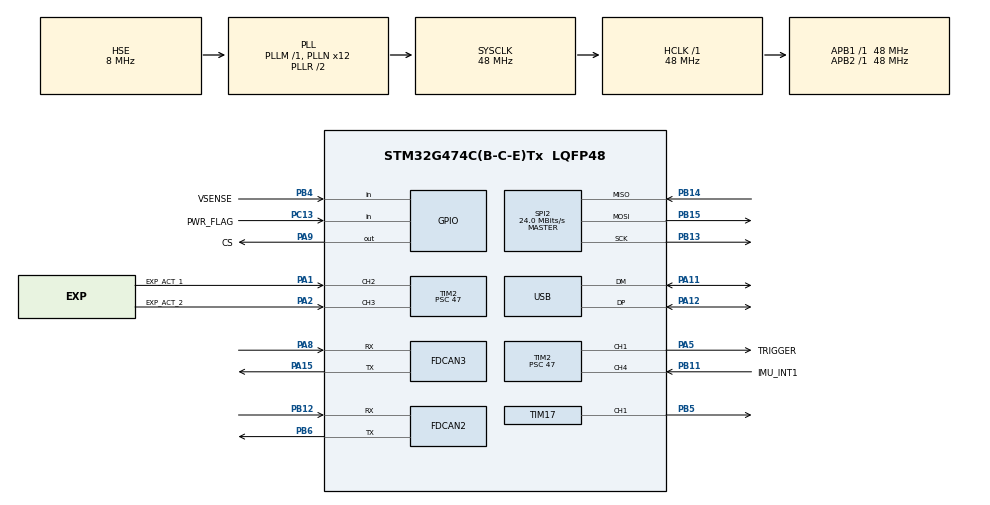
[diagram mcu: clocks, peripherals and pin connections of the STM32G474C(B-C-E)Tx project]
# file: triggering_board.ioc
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FDCAN2.AutoRetransmission=DISABLE
FDCAN2.CalculateBaudRateNominal=500000
FDCAN2.CalculateTimeBitNominal=2000
FDCAN2.CalculateTimeQuantumNominal=20.833333333333332
FDCAN2.DataPrescaler=24
FDCAN2.DataTimeSeg1=2
FDCAN2.FrameFormat=FDCAN_FRAME_CLASSIC
FDCAN2.Mode=FDCAN_MODE_NORMAL
FDCAN2.NominalPrescaler=1
FDCAN2.NominalSyncJumpWidth=12
FDCAN2.NominalTimeSeg1=83
FDCAN2.NominalTimeSeg2=12
FDCAN2.StdFiltersNbr=1
FDCAN3.AutoRetransmission=DISABLE
FDCAN3.CalculateBaudRateNominal=500000
FDCAN3.CalculateTimeBitNominal=2000
FDCAN3.CalculateTimeQuantumNominal=20.833333333333332
FDCAN3.DataPrescaler=24
FDCAN3.DataTimeSeg1=2
FDCAN3.FrameFormat=FDCAN_FRAME_FD_NO_BRS
FDCAN3.Mode=FDCAN_MODE_NORMAL
FDCAN3.NominalPrescaler=1
FDCAN3.NominalSyncJumpWidth=12
FDCAN3.NominalTimeSeg1=83
FDCAN3.NominalTimeSeg2=12
FDCAN3.StdFiltersNbr=1
Mcu.Family=STM32G4
Mcu.Name=STM32G474C(B-C-E)Tx
Mcu.Package=LQFP48
NVIC.FDCAN2_IT0_IRQn=true\:0\:0\:false\:false\:true\:true\:true\:true
NVIC.FDCAN3_IT0_IRQn=true\:0\:0\:false\:false\:true\:true\:true\:true
NVIC.PriorityGroup=NVIC_PRIORITYGROUP_4
NVIC.TIM2_IRQn=true\:0\:0\:false\:false\:true\:true\:true\:true
PA1.GPIO_Label=EXP_ACT_1
PA1.Signal=S_TIM2_CH2
PA11.Mode=Device
PA11.Signal=USB_DM
PA12.Mode=Device
PA12.Signal=USB_DP
PA13.Mode=Trace_Asynchronous_SW
PA13.Signal=SYS_JTMS-SWDIO
PA14.Mode=Trace_Asynchronous_SW
PA14.Signal=SYS_JTCK-SWCLK
PA15.Mode=FDCAN_Activate
PA15.Signal=FDCAN3_TX
PA2.GPIO_Label=EXP_ACT_2
PA2.Signal=S_TIM2_CH3
PA5.GPIO_Label=TRIGGER
PA5.Signal=S_TIM2_CH1
PA8.Mode=FDCAN_Activate
PA8.Signal=FDCAN3_RX
PA9.GPIO_Label=CS
PA9.Signal=GPIO_Output
PB11.GPIO_Label=IMU_INT1
PB11.Signal=S_TIM2_CH4
PB12.Mode=FDCAN_Activate
PB12.Signal=FDCAN2_RX
PB13.Mode=Full_Duplex_Master
PB13.Signal=SPI2_SCK
PB14.Mode=Full_Duplex_Master
PB14.Signal=SPI2_MISO
PB15.Mode=Full_Duplex_Master
PB15.Signal=SPI2_MOSI
PB3.Mode=Trace_Asynchronous_SW
PB3.Signal=SYS_JTDO-SWO
PB4.GPIO_Label=VSENSE
PB4.Signal=GPIO_Input
PB5.Signal=S_TIM17_CH1
PB6.Mode=FDCAN_Activate
PB6.Signal=FDCAN2_TX
PC13.GPIO_Label=PWR_FLAG
PC13.Signal=GPIO_Input
PC14-OSC32_IN.Mode=LSE-External-Oscillator
PC14-OSC32_IN.Signal=RCC_OSC32_IN
PC15-OSC32_OUT.Mode=LSE-External-Oscillator
PC15-OSC32_OUT.Signal=RCC_OSC32_OUT
PF0-OSC_IN.Mode=HSE-External-Oscillator
PF0-OSC_IN.Signal=RCC_OSC_IN
PF1-OSC_OUT.Mode=HSE-External-Oscillator
PF1-OSC_OUT.Signal=RCC_OSC_OUT
ProjectManager.HeapSize=0x200
ProjectManager.StackSize=0x400
ProjectManager.TargetToolchain=STM32CubeIDE
RCC.ADC12Freq_Value=48000000
RCC.ADC345Freq_Value=48000000
RCC.AHBFreq_Value=48000000
RCC.APB1Freq_Value=48000000
RCC.APB1TimFreq_Value=48000000
RCC.APB2Freq_Value=48000000
RCC.APB2TimFreq_Value=48000000
RCC.CortexFreq_Value=48000000
RCC.EXTERNAL_CLOCK_VALUE=12288000
RCC.HCLKFreq_Value=48000000
RCC.HSE_VALUE=8000000
RCC.HSI48_VALUE=48000000
RCC.HSI_VALUE=16000000
RCC.PLLN=12
RCC.PLLSourceVirtual=RCC_PLLSOURCE_HSE
RCC.SYSCLKFreq_VALUE=48000000
RCC.SYSCLKSource=RCC_SYSCLKSOURCE_PLLCLK
RCC.USBFreq_Value=48000000
RCC.VCOOutputFreq_Value=96000000
SH.S_TIM17_CH1.0=TIM17_CH1,PWM Generation1 CH1
SH.S_TIM2_CH1.0=TIM2_CH1,Output Compare1 CH1
SH.S_TIM2_CH2.0=TIM2_CH2,Input_Capture2_from_TI2
SH.S_TIM2_CH3.0=TIM2_CH3,Input_Capture3_from_TI3
SH.S_TIM2_CH4.0=TIM2_CH4,Input_Capture4_from_TI4
SPI2.BaudRatePrescaler=SPI_BAUDRATEPRESCALER_2
SPI2.CLKPhase=SPI_PHASE_1EDGE
SPI2.CLKPolarity=SPI_POLARITY_LOW
SPI2.CalculateBaudRate=24.0 MBits/s
SPI2.DataSize=SPI_DATASIZE_8BIT
SPI2.Direction=SPI_DIRECTION_2LINES
SPI2.Mode=SPI_MODE_MASTER
SPI2.VirtualType=VM_MASTER
TIM17.Channel=TIM_CHANNEL_1
TIM17.PeriodNoDither=999
TIM17.Prescaler=47
TIM17.PulseNoDither_1=100
TIM2.Channel-Input_Capture2_from_TI2=TIM_CHANNEL_2
TIM2.Channel-Input_Capture3_from_TI3=TIM_CHANNEL_3
TIM2.Channel-Input_Capture4_from_TI4=TIM_CHANNEL_4
TIM2.Channel-Output\ Compare1\ CH1=TIM_CHANNEL_1
TIM2.ICPolarity_CH2=TIM_INPUTCHANNELPOLARITY_BOTHEDGE
TIM2.ICPolarity_CH3=TIM_INPUTCHANNELPOLARITY_BOTHEDGE
TIM2.OCMode_1=TIM_OCMODE_TOGGLE
TIM2.Prescaler=47
TIM2.PulseNoDither_1=4294967295
VP_SYS_VS_DBSignals.Mode=DisableDeadBatterySignals
VP_TIM17_VS_ClockSourceINT.Mode=Enable_Timer
VP_TIM2_VS_ClockSourceINT.Mode=Internal
board=custom

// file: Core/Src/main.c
/* USER CODE BEGIN Header */
/**
  ******************************************************************************
  * @file           : main.c
  * @brief          : Main program body
  ******************************************************************************
  * @attention
  *
  * Copyright (c) 2026 STMicroelectronics.
  * All rights reserved.
  *
  * This software is licensed under terms that can be found in the LICENSE file
  * in the root directory of this software component.
  * If no LICENSE file comes with this software, it is provided AS-IS.
  *
  ******************************************************************************
  */
/* USER CODE END Header */
#include "main.h"

FDCAN_HandleTypeDef hfdcan2;
FDCAN_HandleTypeDef hfdcan3;

SPI_HandleTypeDef hspi2;

TIM_HandleTypeDef htim2;
TIM_HandleTypeDef htim17;

PCD_HandleTypeDef hpcd_USB_FS;

void SystemClock_Config(void);
static void MX_GPIO_Init(void);
static void MX_FDCAN2_Init(void);
static void MX_FDCAN3_Init(void);
static void MX_SPI2_Init(void);
static void MX_USB_PCD_Init(void);
static void MX_TIM2_Init(void);
static void MX_TIM17_Init(void);

int main(void)
{

  /* MCU Configuration--------------------------------------------------------*/

  /* Reset of all peripherals, Initializes the Flash interface and the Systick. */
  HAL_Init();

  /* Configure the system clock */
  SystemClock_Config();

  /* Initialize all configured peripherals */
  MX_GPIO_Init();
  MX_FDCAN2_Init();
  MX_FDCAN3_Init();
  MX_SPI2_Init();
  MX_USB_PCD_Init();
  MX_TIM2_Init();
  MX_TIM17_Init();
  /* USER CODE BEGIN 2 */

  // Configure CAN
  configure_fdcan();

  // Start timer channels
  HAL_TIM_OC_Start_IT(&htim2, TIM_CHANNEL_1); // Start TRIGGER channel
  HAL_TIM_OC_Start_IT(&htim2, TIM_CHANNEL_2); // Start EXP_ACT_1 channel
  HAL_TIM_IC_Start_IT(&htim2, TIM_CHANNEL_3); // Start EXP_ACT_2 channel
  HAL_TIM_IC_Start_IT(&htim2, TIM_CHANNEL_4); // Start IMU_INT1 channel
  HAL_TIM_PWM_Start(&htim17, TIM_CHANNEL_1);

  /* USER CODE END 2 */

  /* Infinite loop */
  /* USER CODE BEGIN WHILE */
  while (1)
  {

	  state_machine_handler();

    /* USER CODE END WHILE */

  }
}

void SystemClock_Config(void)
{
  RCC_OscInitTypeDef RCC_OscInitStruct = {0};
  RCC_ClkInitTypeDef RCC_ClkInitStruct = {0};

  /** Configure the main internal regulator output voltage
  */
  HAL_PWREx_ControlVoltageScaling(PWR_REGULATOR_VOLTAGE_SCALE1);

  /** Initializes the RCC Oscillators according to the specified parameters
  * in the RCC_OscInitTypeDef structure.
  */
  RCC_OscInitStruct.OscillatorType = RCC_OSCILLATORTYPE_HSE;
  RCC_OscInitStruct.HSEState = RCC_HSE_ON;
  RCC_OscInitStruct.PLL.PLLState = RCC_PLL_ON;
  RCC_OscInitStruct.PLL.PLLSource = RCC_PLLSOURCE_HSE;
  RCC_OscInitStruct.PLL.PLLM = RCC_PLLM_DIV1;
  RCC_OscInitStruct.PLL.PLLN = 12;
  RCC_OscInitStruct.PLL.PLLP = RCC_PLLP_DIV2;
  RCC_OscInitStruct.PLL.PLLQ = RCC_PLLQ_DIV2;
  RCC_OscInitStruct.PLL.PLLR = RCC_PLLR_DIV2;
  if (HAL_RCC_OscConfig(&RCC_OscInitStruct) != HAL_OK)
  {
    Error_Handler();
  }

  /** Initializes the CPU, AHB and APB buses clocks
  */
  RCC_ClkInitStruct.ClockType = RCC_CLOCKTYPE_HCLK|RCC_CLOCKTYPE_SYSCLK
                              |RCC_CLOCKTYPE_PCLK1|RCC_CLOCKTYPE_PCLK2;
  RCC_ClkInitStruct.SYSCLKSource = RCC_SYSCLKSOURCE_PLLCLK;
  RCC_ClkInitStruct.AHBCLKDivider = RCC_SYSCLK_DIV1;
  RCC_ClkInitStruct.APB1CLKDivider = RCC_HCLK_DIV1;
  RCC_ClkInitStruct.APB2CLKDivider = RCC_HCLK_DIV1;

  if (HAL_RCC_ClockConfig(&RCC_ClkInitStruct, FLASH_LATENCY_1) != HAL_OK)
  {
    Error_Handler();
  }
}

static void MX_FDCAN2_Init(void)
{

  hfdcan2.Instance = FDCAN2;
  hfdcan2.Init.ClockDivider = FDCAN_CLOCK_DIV1;
  hfdcan2.Init.FrameFormat = FDCAN_FRAME_CLASSIC;
  hfdcan2.Init.Mode = FDCAN_MODE_NORMAL;
  hfdcan2.Init.AutoRetransmission = DISABLE;
  hfdcan2.Init.TransmitPause = DISABLE;
  hfdcan2.Init.ProtocolException = DISABLE;
  hfdcan2.Init.NominalPrescaler = 1;
  hfdcan2.Init.NominalSyncJumpWidth = 12;
  hfdcan2.Init.NominalTimeSeg1 = 83;
  hfdcan2.Init.NominalTimeSeg2 = 12;
  hfdcan2.Init.DataPrescaler = 24;
  hfdcan2.Init.DataSyncJumpWidth = 1;
  hfdcan2.Init.DataTimeSeg1 = 2;
  hfdcan2.Init.DataTimeSeg2 = 1;
  hfdcan2.Init.StdFiltersNbr = 1;
  hfdcan2.Init.ExtFiltersNbr = 0;
  hfdcan2.Init.TxFifoQueueMode = FDCAN_TX_FIFO_OPERATION;
  if (HAL_FDCAN_Init(&hfdcan2) != HAL_OK)
  {
    Error_Handler();
  }

}

static void MX_FDCAN3_Init(void)
{

  hfdcan3.Instance = FDCAN3;
  hfdcan3.Init.ClockDivider = FDCAN_CLOCK_DIV1;
  hfdcan3.Init.FrameFormat = FDCAN_FRAME_FD_NO_BRS;
  hfdcan3.Init.Mode = FDCAN_MODE_NORMAL;
  hfdcan3.Init.AutoRetransmission = DISABLE;
  hfdcan3.Init.TransmitPause = DISABLE;
  hfdcan3.Init.ProtocolException = DISABLE;
  hfdcan3.Init.NominalPrescaler = 1;
  hfdcan3.Init.NominalSyncJumpWidth = 12;
  hfdcan3.Init.NominalTimeSeg1 = 83;
  hfdcan3.Init.NominalTimeSeg2 = 12;
  hfdcan3.Init.DataPrescaler = 24;
  hfdcan3.Init.DataSyncJumpWidth = 1;
  hfdcan3.Init.DataTimeSeg1 = 2;
  hfdcan3.Init.DataTimeSeg2 = 1;
  hfdcan3.Init.StdFiltersNbr = 1;
  hfdcan3.Init.ExtFiltersNbr = 0;
  hfdcan3.Init.TxFifoQueueMode = FDCAN_TX_FIFO_OPERATION;
  if (HAL_FDCAN_Init(&hfdcan3) != HAL_OK)
  {
    Error_Handler();
  }

}

static void MX_SPI2_Init(void)
{

  /* SPI2 parameter configuration*/
  hspi2.Instance = SPI2;
  hspi2.Init.Mode = SPI_MODE_MASTER;
  hspi2.Init.Direction = SPI_DIRECTION_2LINES;
  hspi2.Init.DataSize = SPI_DATASIZE_8BIT;
  hspi2.Init.CLKPolarity = SPI_POLARITY_LOW;
  hspi2.Init.CLKPhase = SPI_PHASE_1EDGE;
  hspi2.Init.NSS = SPI_NSS_SOFT;
  hspi2.Init.BaudRatePrescaler = SPI_BAUDRATEPRESCALER_2;
  hspi2.Init.FirstBit = SPI_FIRSTBIT_MSB;
  hspi2.Init.TIMode = SPI_TIMODE_DISABLE;
  hspi2.Init.CRCCalculation = SPI_CRCCALCULATION_DISABLE;
  hspi2.Init.CRCPolynomial = 7;
  hspi2.Init.CRCLength = SPI_CRC_LENGTH_DATASIZE;
  hspi2.Init.NSSPMode = SPI_NSS_PULSE_ENABLE;
  if (HAL_SPI_Init(&hspi2) != HAL_OK)
  {
    Error_Handler();
  }

}

static void MX_TIM2_Init(void)
{

  TIM_ClockConfigTypeDef sClockSourceConfig = {0};
  TIM_MasterConfigTypeDef sMasterConfig = {0};
  TIM_OC_InitTypeDef sConfigOC = {0};
  TIM_IC_InitTypeDef sConfigIC = {0};

  htim2.Instance = TIM2;
  htim2.Init.Prescaler = 47;
  htim2.Init.CounterMode = TIM_COUNTERMODE_UP;
  htim2.Init.Period = 4294967295;
  htim2.Init.ClockDivision = TIM_CLOCKDIVISION_DIV1;
  htim2.Init.AutoReloadPreload = TIM_AUTORELOAD_PRELOAD_DISABLE;
  if (HAL_TIM_Base_Init(&htim2) != HAL_OK)
  {
    Error_Handler();
  }
  sClockSourceConfig.ClockSource = TIM_CLOCKSOURCE_INTERNAL;
  if (HAL_TIM_ConfigClockSource(&htim2, &sClockSourceConfig) != HAL_OK)
  {
    Error_Handler();
  }
  if (HAL_TIM_OC_Init(&htim2) != HAL_OK)
  {
    Error_Handler();
  }
  if (HAL_TIM_IC_Init(&htim2) != HAL_OK)
  {
    Error_Handler();
  }
  sMasterConfig.MasterOutputTrigger = TIM_TRGO_RESET;
  sMasterConfig.MasterSlaveMode = TIM_MASTERSLAVEMODE_DISABLE;
  if (HAL_TIMEx_MasterConfigSynchronization(&htim2, &sMasterConfig) != HAL_OK)
  {
    Error_Handler();
  }
  sConfigOC.OCMode = TIM_OCMODE_TOGGLE;
  sConfigOC.Pulse = 4294967295;
  sConfigOC.OCPolarity = TIM_OCPOLARITY_HIGH;
  sConfigOC.OCFastMode = TIM_OCFAST_DISABLE;
  if (HAL_TIM_OC_ConfigChannel(&htim2, &sConfigOC, TIM_CHANNEL_1) != HAL_OK)
  {
    Error_Handler();
  }
  sConfigIC.ICPolarity = TIM_INPUTCHANNELPOLARITY_BOTHEDGE;
  sConfigIC.ICSelection = TIM_ICSELECTION_DIRECTTI;
  sConfigIC.ICPrescaler = TIM_ICPSC_DIV1;
  sConfigIC.ICFilter = 0;
  if (HAL_TIM_IC_ConfigChannel(&htim2, &sConfigIC, TIM_CHANNEL_2) != HAL_OK)
  {
    Error_Handler();
  }
  if (HAL_TIM_IC_ConfigChannel(&htim2, &sConfigIC, TIM_CHANNEL_3) != HAL_OK)
  {
    Error_Handler();
  }
  sConfigIC.ICPolarity = TIM_INPUTCHANNELPOLARITY_RISING;
  if (HAL_TIM_IC_ConfigChannel(&htim2, &sConfigIC, TIM_CHANNEL_4) != HAL_OK)
  {
    Error_Handler();
  }
  HAL_TIM_MspPostInit(&htim2);

}

static void MX_TIM17_Init(void)
{

  TIM_OC_InitTypeDef sConfigOC = {0};
  TIM_BreakDeadTimeConfigTypeDef sBreakDeadTimeConfig = {0};

  htim17.Instance = TIM17;
  htim17.Init.Prescaler = 47;
  htim17.Init.CounterMode = TIM_COUNTERMODE_UP;
  htim17.Init.Period = 999;
  htim17.Init.ClockDivision = TIM_CLOCKDIVISION_DIV1;
  htim17.Init.RepetitionCounter = 0;
  htim17.Init.AutoReloadPreload = TIM_AUTORELOAD_PRELOAD_DISABLE;
  if (HAL_TIM_Base_Init(&htim17) != HAL_OK)
  {
    Error_Handler();
  }
  if (HAL_TIM_PWM_Init(&htim17) != HAL_OK)
  {
    Error_Handler();
  }
  sConfigOC.OCMode = TIM_OCMODE_PWM1;
  sConfigOC.Pulse = 100;
  sConfigOC.OCPolarity = TIM_OCPOLARITY_HIGH;
  sConfigOC.OCNPolarity = TIM_OCNPOLARITY_HIGH;
  sConfigOC.OCFastMode = TIM_OCFAST_DISABLE;
  sConfigOC.OCIdleState = TIM_OCIDLESTATE_RESET;
  sConfigOC.OCNIdleState = TIM_OCNIDLESTATE_RESET;
  if (HAL_TIM_PWM_ConfigChannel(&htim17, &sConfigOC, TIM_CHANNEL_1) != HAL_OK)
  {
    Error_Handler();
  }
  sBreakDeadTimeConfig.OffStateRunMode = TIM_OSSR_DISABLE;
  sBreakDeadTimeConfig.OffStateIDLEMode = TIM_OSSI_DISABLE;
  sBreakDeadTimeConfig.LockLevel = TIM_LOCKLEVEL_OFF;
  sBreakDeadTimeConfig.DeadTime = 0;
  sBreakDeadTimeConfig.BreakState = TIM_BREAK_DISABLE;
  sBreakDeadTimeConfig.BreakPolarity = TIM_BREAKPOLARITY_HIGH;
  sBreakDeadTimeConfig.BreakFilter = 0;
  sBreakDeadTimeConfig.AutomaticOutput = TIM_AUTOMATICOUTPUT_DISABLE;
  if (HAL_TIMEx_ConfigBreakDeadTime(&htim17, &sBreakDeadTimeConfig) != HAL_OK)
  {
    Error_Handler();
  }
  HAL_TIM_MspPostInit(&htim17);

}

static void MX_USB_PCD_Init(void)
{

  hpcd_USB_FS.Instance = USB;
  hpcd_USB_FS.Init.dev_endpoints = 8;
  hpcd_USB_FS.Init.speed = PCD_SPEED_FULL;
  hpcd_USB_FS.Init.phy_itface = PCD_PHY_EMBEDDED;
  hpcd_USB_FS.Init.Sof_enable = DISABLE;
  hpcd_USB_FS.Init.low_power_enable = DISABLE;
  hpcd_USB_FS.Init.lpm_enable = DISABLE;
  hpcd_USB_FS.Init.battery_charging_enable = DISABLE;
  if (HAL_PCD_Init(&hpcd_USB_FS) != HAL_OK)
  {
    Error_Handler();
  }

}

static void MX_GPIO_Init(void)
{
  GPIO_InitTypeDef GPIO_InitStruct = {0};

  /* GPIO Ports Clock Enable */
  __HAL_RCC_GPIOC_CLK_ENABLE();
  __HAL_RCC_GPIOF_CLK_ENABLE();
  __HAL_RCC_GPIOA_CLK_ENABLE();
  __HAL_RCC_GPIOB_CLK_ENABLE();

  /*Configure GPIO pin Output Level */
  HAL_GPIO_WritePin(CS_GPIO_Port, CS_Pin, GPIO_PIN_RESET);

  /*Configure GPIO pin : PWR_FLAG_Pin */
  GPIO_InitStruct.Pin = PWR_FLAG_Pin;
  GPIO_InitStruct.Mode = GPIO_MODE_INPUT;
  GPIO_InitStruct.Pull = GPIO_NOPULL;
  HAL_GPIO_Init(PWR_FLAG_GPIO_Port, &GPIO_InitStruct);

  /*Configure GPIO pin : CS_Pin */
  GPIO_InitStruct.Pin = CS_Pin;
  GPIO_InitStruct.Mode = GPIO_MODE_OUTPUT_PP;
  GPIO_InitStruct.Pull = GPIO_NOPULL;
  GPIO_InitStruct.Speed = GPIO_SPEED_FREQ_LOW;
  HAL_GPIO_Init(CS_GPIO_Port, &GPIO_InitStruct);

  /*Configure GPIO pin : VSENSE_Pin */
  GPIO_InitStruct.Pin = VSENSE_Pin;
  GPIO_InitStruct.Mode = GPIO_MODE_INPUT;
  GPIO_InitStruct.Pull = GPIO_NOPULL;
  HAL_GPIO_Init(VSENSE_GPIO_Port, &GPIO_InitStruct);

}

void Error_Handler(void)
{
  __disable_irq();
  while (1)
  {
  }
}
